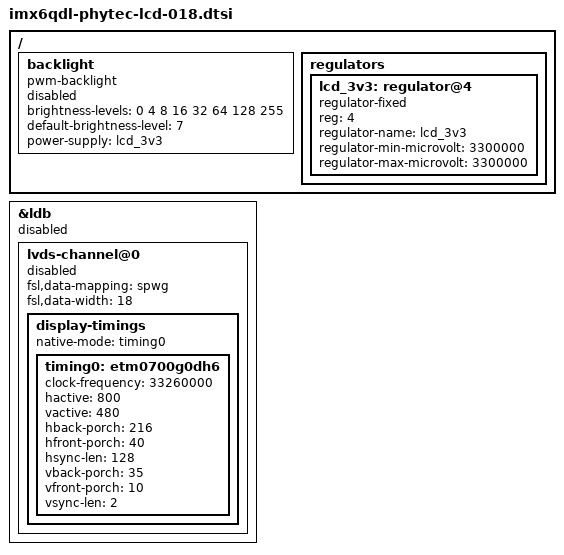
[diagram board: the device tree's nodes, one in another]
/*
 * Copyright (C) 2014 Christian Hemp <c.hemp@phytec.de> PHYTEC Messtechnik GmbH
 *
 * This program is free software; you can redistribute it and/or modify
 * it under the terms of the GNU General Public License version 2 as
 * published by the Free Software Foundation.
 */

/*
 * The board specific DTS file have to:
 *  - Specify pwms and enable gpios for backlight
 *  - Mux the display enable pins if available
*/


/ {
	backlight: backlight {
		compatible = "pwm-backlight";
		brightness-levels = <0 4 8 16 32 64 128 255>;
		default-brightness-level = <7>;
		power-supply = <&lcd_3v3>;
		status = "disabled";
	};

	regulators {
		lcd_3v3: regulator@4 {
			compatible = "regulator-fixed";
			reg = <4>;
			regulator-name = "lcd_3v3";
			regulator-min-microvolt = <3300000>;
			regulator-max-microvolt = <3300000>;
		};
	};
};


&ldb {
	status = "disabled";

	lvds-channel@0 {
		fsl,data-mapping = "spwg";
		fsl,data-width = <18>;
		status = "disabled";

		display-timings {
			native-mode = <&timing0>;
			timing0: etm0700g0dh6 {
				clock-frequency = <33260000>;
				hactive = <800>;
				vactive = <480>;
				hback-porch = <216>;
				hfront-porch = <40>;
				hsync-len = <128>;
				vback-porch = <35>;
				vfront-porch = <10>;
				vsync-len = <2>;
			};
		};
	};
};

